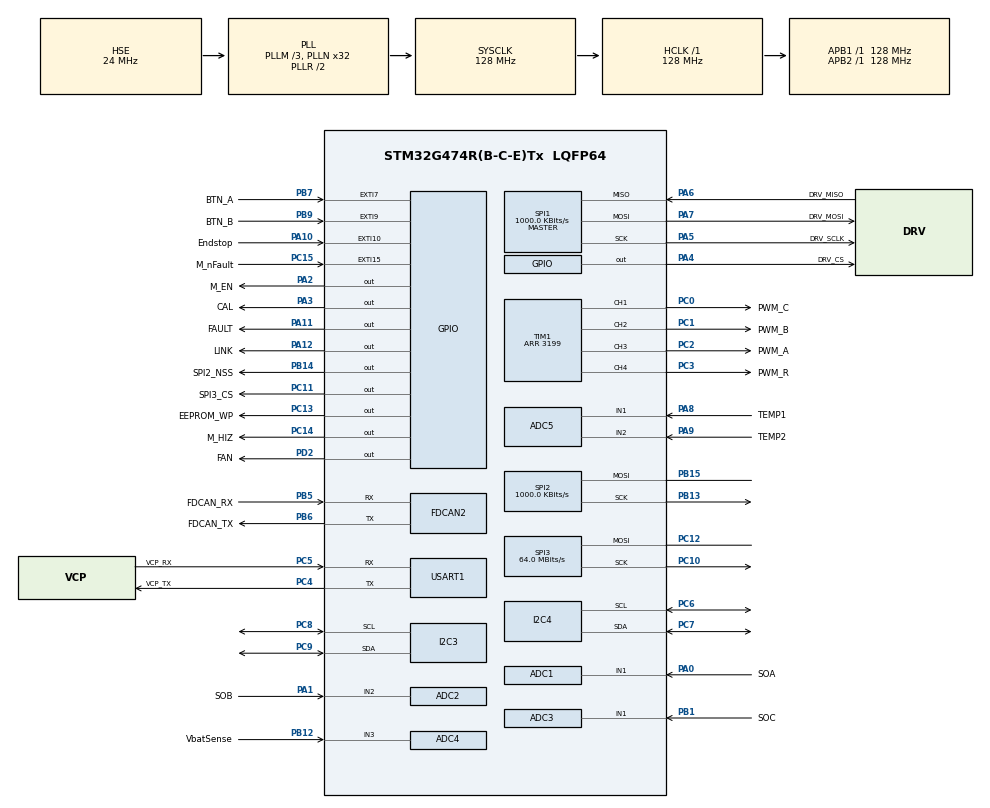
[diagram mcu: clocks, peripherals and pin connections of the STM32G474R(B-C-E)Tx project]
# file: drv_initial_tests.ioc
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ADC1.Channel-0\#ChannelRegularConversion=ADC_CHANNEL_1
ADC1.ClockPrescaler=ADC_CLOCK_ASYNC_DIV10
ADC1.ContinuousConvMode=DISABLE
ADC1.DMAContinuousRequests=ENABLE
ADC1.EnableInjectedConversion=DISABLE
ADC1.ExternalTrigConv=ADC_EXTERNALTRIG_T1_TRGO2
ADC1.NbrOfConversionFlag=1
ADC1.OffsetNumber-0\#ChannelRegularConversion=ADC_OFFSET_NONE
ADC1.Rank-0\#ChannelRegularConversion=1
ADC1.SamplingTime-0\#ChannelRegularConversion=ADC_SAMPLETIME_6CYCLES_5
ADC1.master=1
ADC2.Channel-0\#ChannelRegularConversion=ADC_CHANNEL_2
ADC2.ClockPrescaler=ADC_CLOCK_ASYNC_DIV10
ADC2.ContinuousConvMode=DISABLE
ADC2.DMAContinuousRequests=ENABLE
ADC2.ExternalTrigConv=ADC_EXTERNALTRIG_T1_TRGO2
ADC2.NbrOfConversionFlag=1
ADC2.OffsetNumber-0\#ChannelRegularConversion=ADC_OFFSET_NONE
ADC2.Rank-0\#ChannelRegularConversion=1
ADC2.SamplingTime-0\#ChannelRegularConversion=ADC_SAMPLETIME_6CYCLES_5
ADC3.Channel-5\#ChannelRegularConversion=ADC_CHANNEL_1
ADC3.ClockPrescaler=ADC_CLOCK_ASYNC_DIV10
ADC3.ContinuousConvMode=DISABLE
ADC3.DMAContinuousRequests=ENABLE
ADC3.ExternalTrigConv=ADC_EXTERNALTRIG_T1_TRGO2
ADC3.NbrOfConversionFlag=1
ADC3.OffsetNumber-5\#ChannelRegularConversion=ADC_OFFSET_NONE
ADC3.Rank-5\#ChannelRegularConversion=1
ADC3.SamplingTime-5\#ChannelRegularConversion=ADC_SAMPLETIME_6CYCLES_5
ADC3.master=1
ADC4.Channel-8\#ChannelRegularConversion=ADC_CHANNEL_3
ADC4.ClockPrescaler=ADC_CLOCK_ASYNC_DIV10
ADC4.NbrOfConversionFlag=1
ADC4.OffsetNumber-8\#ChannelRegularConversion=ADC_OFFSET_NONE
ADC4.Rank-8\#ChannelRegularConversion=1
ADC4.SamplingTime-8\#ChannelRegularConversion=ADC_SAMPLETIME_2CYCLES_5
ADC5.Channel-0\#ChannelRegularConversion=ADC_CHANNEL_1
ADC5.ClockPrescaler=ADC_CLOCK_ASYNC_DIV10
ADC5.ContinuousConvMode=ENABLE
ADC5.NbrOfConversionFlag=1
ADC5.OffsetNumber-0\#ChannelRegularConversion=ADC_OFFSET_NONE
ADC5.Rank-0\#ChannelRegularConversion=1
ADC5.SamplingTime-0\#ChannelRegularConversion=ADC_SAMPLETIME_2CYCLES_5
Dma.ADC1.0.Direction=DMA_PERIPH_TO_MEMORY
Dma.ADC1.0.EventEnable=DISABLE
Dma.ADC1.0.Instance=DMA1_Channel1
Dma.ADC1.0.MemDataAlignment=DMA_MDATAALIGN_HALFWORD
Dma.ADC1.0.MemInc=DMA_MINC_DISABLE
Dma.ADC1.0.Mode=DMA_CIRCULAR
Dma.ADC1.0.PeriphDataAlignment=DMA_PDATAALIGN_HALFWORD
Dma.ADC1.0.PeriphInc=DMA_PINC_DISABLE
Dma.ADC1.0.Polarity=HAL_DMAMUX_REQ_GEN_RISING
Dma.ADC1.0.Priority=DMA_PRIORITY_LOW
Dma.ADC1.0.RequestNumber=1
Dma.ADC1.0.SignalID=NONE
Dma.ADC1.0.SyncEnable=DISABLE
Dma.ADC1.0.SyncPolarity=HAL_DMAMUX_SYNC_NO_EVENT
Dma.ADC1.0.SyncRequestNumber=1
Dma.ADC1.0.SyncSignalID=NONE
Dma.ADC2.1.Direction=DMA_PERIPH_TO_MEMORY
Dma.ADC2.1.EventEnable=DISABLE
Dma.ADC2.1.Instance=DMA1_Channel2
Dma.ADC2.1.MemDataAlignment=DMA_MDATAALIGN_HALFWORD
Dma.ADC2.1.MemInc=DMA_MINC_DISABLE
Dma.ADC2.1.Mode=DMA_CIRCULAR
Dma.ADC2.1.PeriphDataAlignment=DMA_PDATAALIGN_HALFWORD
Dma.ADC2.1.PeriphInc=DMA_PINC_DISABLE
Dma.ADC2.1.Polarity=HAL_DMAMUX_REQ_GEN_RISING
Dma.ADC2.1.Priority=DMA_PRIORITY_LOW
Dma.ADC2.1.RequestNumber=1
Dma.ADC2.1.SignalID=NONE
Dma.ADC2.1.SyncEnable=DISABLE
Dma.ADC2.1.SyncPolarity=HAL_DMAMUX_SYNC_NO_EVENT
Dma.ADC2.1.SyncRequestNumber=1
Dma.ADC2.1.SyncSignalID=NONE
Dma.ADC3.2.Direction=DMA_PERIPH_TO_MEMORY
Dma.ADC3.2.EventEnable=DISABLE
Dma.ADC3.2.Instance=DMA1_Channel3
Dma.ADC3.2.MemDataAlignment=DMA_MDATAALIGN_HALFWORD
Dma.ADC3.2.MemInc=DMA_MINC_DISABLE
Dma.ADC3.2.Mode=DMA_CIRCULAR
Dma.ADC3.2.PeriphDataAlignment=DMA_PDATAALIGN_HALFWORD
Dma.ADC3.2.PeriphInc=DMA_PINC_DISABLE
Dma.ADC3.2.Polarity=HAL_DMAMUX_REQ_GEN_RISING
Dma.ADC3.2.Priority=DMA_PRIORITY_LOW
Dma.ADC3.2.RequestNumber=1
Dma.ADC3.2.SignalID=NONE
Dma.ADC3.2.SyncEnable=DISABLE
Dma.ADC3.2.SyncPolarity=HAL_DMAMUX_SYNC_NO_EVENT
Dma.ADC3.2.SyncRequestNumber=1
Dma.ADC3.2.SyncSignalID=NONE
Dma.Request0=ADC1
Dma.Request1=ADC2
Dma.Request2=ADC3
FDCAN2.AutoRetransmission=ENABLE
FDCAN2.CalculateBaudRateNominal=2666666
FDCAN2.CalculateTimeBitNominal=375
FDCAN2.CalculateTimeQuantumNominal=125.0
I2C3.Timing=0x20E2A7F4
I2C4.Timing=0x20E2A7F4
IWDG.Prescaler=IWDG_PRESCALER_32
Mcu.Family=STM32G4
Mcu.Name=STM32G474R(B-C-E)Tx
Mcu.Package=LQFP64
NVIC.DMA1_Channel1_IRQn=true\:0\:0\:false\:false\:true\:false\:true\:true
NVIC.DMA1_Channel2_IRQn=true\:0\:0\:false\:false\:true\:false\:true\:true
NVIC.DMA1_Channel3_IRQn=true\:0\:0\:false\:false\:true\:false\:true\:true
NVIC.EXTI15_10_IRQn=true\:3\:0\:true\:false\:true\:true\:true\:true
NVIC.EXTI9_5_IRQn=true\:2\:0\:true\:false\:true\:true\:true\:true
NVIC.PriorityGroup=NVIC_PRIORITYGROUP_4
NVIC.TIM1_UP_TIM16_IRQn=true\:0\:0\:false\:false\:true\:true\:true\:true
NVIC.TIM6_DAC_IRQn=true\:1\:0\:true\:false\:true\:true\:true\:true
NVIC.TIM7_DAC_IRQn=true\:2\:0\:true\:false\:true\:true\:true\:true
PA0.GPIO_Label=SOA
PA0.Mode=IN1-Single-Ended
PA0.Signal=ADC1_IN1
PA1.GPIO_Label=SOB
PA1.Mode=IN2-Single-Ended
PA1.Signal=ADC2_IN2
PA10.GPIO_Label=Endstop
PA10.Signal=GPXTI10
PA11.GPIO_Label=FAULT
PA11.PinState=GPIO_PIN_SET
PA11.Signal=GPIO_Output
PA12.GPIO_Label=LINK
PA12.PinState=GPIO_PIN_SET
PA12.Signal=GPIO_Output
PA13.Mode=JTAG_5_pins
PA13.Signal=SYS_JTMS-SWDIO
PA14.Mode=JTAG_5_pins
PA14.Signal=SYS_JTCK-SWCLK
PA15.Mode=JTAG_5_pins
PA15.Signal=SYS_JTDI
PA2.GPIO_Label=M_EN
PA2.Signal=GPIO_Output
PA3.GPIO_Label=CAL
PA3.Signal=GPIO_Output
PA4.GPIO_Label=DRV_CS
PA4.PinState=GPIO_PIN_SET
PA4.Signal=GPIO_Output
PA5.GPIO_Label=DRV_SCLK
PA5.Mode=Full_Duplex_Master
PA5.Signal=SPI1_SCK
PA6.GPIO_Label=DRV_MISO
PA6.Mode=Full_Duplex_Master
PA6.Signal=SPI1_MISO
PA7.GPIO_Label=DRV_MOSI
PA7.Mode=Full_Duplex_Master
PA7.Signal=SPI1_MOSI
PA8.GPIO_Label=TEMP1
PA8.Mode=IN1-Single-Ended
PA8.Signal=ADC5_IN1
PA9.GPIO_Label=TEMP2
PA9.Mode=IN2-Single-Ended
PA9.Signal=ADC5_IN2
PB1.GPIO_Label=SOC
PB1.Mode=IN1-Single-Ended
PB1.Signal=ADC3_IN1
PB12.GPIO_Label=VbatSense
PB12.Mode=IN3-Single-Ended
PB12.Signal=ADC4_IN3
PB13.Mode=Simplex_Bidirectional_Master
PB13.Signal=SPI2_SCK
PB14.GPIO_Label=SPI2_NSS
PB14.PinState=GPIO_PIN_SET
PB14.Signal=GPIO_Output
PB15.Mode=Simplex_Bidirectional_Master
PB15.Signal=SPI2_MOSI
PB3.Mode=JTAG_5_pins
PB3.Signal=SYS_JTDO-SWO
PB4.Mode=JTAG_5_pins
PB4.Signal=SYS_JTRST
PB5.GPIO_Label=FDCAN_RX
PB5.Mode=FDCAN_Activate
PB5.Signal=FDCAN2_RX
PB6.GPIO_Label=FDCAN_TX
PB6.Mode=FDCAN_Activate
PB6.Signal=FDCAN2_TX
PB7.GPIO_Label=BTN_A
PB7.GPIO_ModeDefaultEXTI=GPIO_MODE_IT_FALLING
PB7.GPIO_PuPd=GPIO_PULLUP
PB7.Signal=GPXTI7
PB9.GPIO_Label=BTN_B
PB9.GPIO_ModeDefaultEXTI=GPIO_MODE_IT_FALLING
PB9.GPIO_PuPd=GPIO_PULLUP
PB9.Signal=GPXTI9
PC0.GPIO_Label=PWM_C
PC0.Signal=S_TIM1_CH1
PC1.GPIO_Label=PWM_B
PC1.Signal=S_TIM1_CH2
PC10.Mode=Simplex_Bidirectional_Master
PC10.Signal=SPI3_SCK
PC11.GPIO_Label=SPI3_CS
PC11.PinState=GPIO_PIN_SET
PC11.Signal=GPIO_Output
PC12.Mode=Simplex_Bidirectional_Master
PC12.Signal=SPI3_MOSI
PC13.GPIO_Label=EEPROM_WP
PC13.Signal=GPIO_Output
PC14-OSC32_IN.GPIO_Label=M_HIZ
PC14-OSC32_IN.Signal=GPIO_Output
PC15-OSC32_OUT.GPIO_Label=M_nFault
PC15-OSC32_OUT.GPIO_ModeDefaultEXTI=GPIO_MODE_IT_FALLING
PC15-OSC32_OUT.Signal=GPXTI15
PC2.GPIO_Label=PWM_A
PC2.Signal=S_TIM1_CH3
PC3.GPIO_Label=PWM_R
PC3.Signal=S_TIM1_CH4
PC4.GPIO_Label=VCP_TX
PC4.Mode=Asynchronous
PC4.Signal=USART1_TX
PC5.GPIO_Label=VCP_RX
PC5.Mode=Asynchronous
PC5.Signal=USART1_RX
PC6.Mode=I2C
PC6.Signal=I2C4_SCL
PC7.Mode=I2C
PC7.Signal=I2C4_SDA
PC8.Mode=I2C
PC8.Signal=I2C3_SCL
PC9.Mode=I2C
PC9.Signal=I2C3_SDA
PD2.GPIO_Label=FAN
PD2.Signal=GPIO_Output
PF0-OSC_IN.Mode=HSE-External-Oscillator
PF0-OSC_IN.Signal=RCC_OSC_IN
PF1-OSC_OUT.Mode=HSE-External-Oscillator
PF1-OSC_OUT.Signal=RCC_OSC_OUT
ProjectManager.HeapSize=0x200
ProjectManager.StackSize=0x400
ProjectManager.TargetToolchain=STM32CubeIDE
RCC.ADC12Freq_Value=128000000
RCC.ADC345Freq_Value=128000000
RCC.AHBFreq_Value=128000000
RCC.APB1Freq_Value=128000000
RCC.APB1TimFreq_Value=128000000
RCC.APB2Freq_Value=128000000
RCC.APB2TimFreq_Value=128000000
RCC.CortexFreq_Value=128000000
RCC.EXTERNAL_CLOCK_VALUE=12288000
RCC.HCLKFreq_Value=128000000
RCC.HSE_VALUE=24000000
RCC.HSI48_VALUE=48000000
RCC.HSI_VALUE=16000000
RCC.LSE_VALUE=32768
RCC.PLLM=RCC_PLLM_DIV3
RCC.PLLN=32
RCC.PLLSourceVirtual=RCC_PLLSOURCE_HSE
RCC.SYSCLKFreq_VALUE=128000000
RCC.SYSCLKSource=RCC_SYSCLKSOURCE_PLLCLK
RCC.USBFreq_Value=128000000
RCC.VCOOutputFreq_Value=256000000
SH.S_TIM1_CH1.0=TIM1_CH1,PWM Generation1 CH1
SH.S_TIM1_CH2.0=TIM1_CH2,PWM Generation2 CH2
SH.S_TIM1_CH3.0=TIM1_CH3,PWM Generation3 CH3
SH.S_TIM1_CH4.0=TIM1_CH4,PWM Generation4 CH4
SPI1.BaudRatePrescaler=SPI_BAUDRATEPRESCALER_128
SPI1.CLKPhase=SPI_PHASE_2EDGE
SPI1.CalculateBaudRate=1000.0 KBits/s
SPI1.DataSize=SPI_DATASIZE_16BIT
SPI1.Direction=SPI_DIRECTION_2LINES
SPI1.Mode=SPI_MODE_MASTER
SPI1.VirtualType=VM_MASTER
SPI2.BaudRatePrescaler=SPI_BAUDRATEPRESCALER_128
SPI2.CLKPhase=SPI_PHASE_2EDGE
SPI2.CalculateBaudRate=1000.0 KBits/s
SPI2.DataSize=SPI_DATASIZE_8BIT
SPI2.Direction=SPI_DIRECTION_1LINE
SPI2.Mode=SPI_MODE_MASTER
SPI2.VirtualType=VM_MASTER
SPI3.CalculateBaudRate=64.0 MBits/s
SPI3.Direction=SPI_DIRECTION_1LINE
SPI3.Mode=SPI_MODE_MASTER
SPI3.VirtualType=VM_MASTER
TIM1.Channel-Output\ Compare5\ No\ Output=TIM_CHANNEL_5
TIM1.Channel-PWM\ Generation1\ CH1=TIM_CHANNEL_1
TIM1.Channel-PWM\ Generation2\ CH2=TIM_CHANNEL_2
TIM1.Channel-PWM\ Generation3\ CH3=TIM_CHANNEL_3
TIM1.Channel-PWM\ Generation4\ CH4=TIM_CHANNEL_4
TIM1.CounterMode=TIM_COUNTERMODE_CENTERALIGNED1
TIM1.OC5Preload=DISABLE
TIM1.OCMode_5=TIM_OCMODE_TOGGLE
TIM1.PeriodNoDither=3199
TIM1.PulseNoDither_5=1599
TIM1.TIM_MasterOutputTrigger2=TIM_TRGO2_OC5REF
TIM6.PeriodNoDither=25599
TIM7.PeriodNoDither=39999
TIM7.Prescaler=15
USART1.VirtualMode-Asynchronous=VM_ASYNC
VP_IWDG_VS_IWDG.Mode=IWDG_Activate
VP_SYS_VS_DBSignals.Mode=DisableDeadBatterySignals
VP_TIM1_VS_ClockSourceINT.Mode=Internal
VP_TIM1_VS_no_output5.Mode=Output Compare5 No Output
VP_TIM6_VS_ClockSourceINT.Mode=Enable_Timer
VP_TIM7_VS_ClockSourceINT.Mode=Enable_Timer
board=custom

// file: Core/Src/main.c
/* USER CODE BEGIN Header */
/**
  ******************************************************************************
  * @file           : main.c
  * @brief          : Main program body
  ******************************************************************************
  * @attention
  *
  * Copyright (c) 2025 STMicroelectronics.
  * All rights reserved.
  *
  * This software is licensed under terms that can be found in the LICENSE file
  * in the root directory of this software component.
  * If no LICENSE file comes with this software, it is provided AS-IS.
  *
  ******************************************************************************
  */
/* USER CODE END Header */
#include "main.h"

/* USER CODE BEGIN Includes */
#include <stdbool.h>
#include <string.h>
#include <stdio.h>
#include <math.h>
#include "TLE_encoder.h"
#include <stdlib.h>
/* USER CODE END Includes */

ADC_HandleTypeDef hadc1;
ADC_HandleTypeDef hadc2;
ADC_HandleTypeDef hadc3;
ADC_HandleTypeDef hadc4;
ADC_HandleTypeDef hadc5;
DMA_HandleTypeDef hdma_adc1;
DMA_HandleTypeDef hdma_adc2;
DMA_HandleTypeDef hdma_adc3;

FDCAN_HandleTypeDef hfdcan2;

I2C_HandleTypeDef hi2c3;
I2C_HandleTypeDef hi2c4;

IWDG_HandleTypeDef hiwdg;

SPI_HandleTypeDef hspi1;
SPI_HandleTypeDef hspi2;
SPI_HandleTypeDef hspi3;

TIM_HandleTypeDef htim1;
TIM_HandleTypeDef htim6;
TIM_HandleTypeDef htim7;

UART_HandleTypeDef huart1;

/* USER CODE BEGIN PV */
//--DRV8323 register definitions------------------------------------------------
// Read-only status registers
#define DRV8323_REG_FAULT_STATUS_1    0x00  // Fault Status Register 1
#define DRV8323_REG_VGS_STATUS_2      0x01  // VGS Fault Status Register 2
// Control and configuration registers
#define DRV8323_REG_DRIVER_CONTROL    0x02  // Driver Control Register
#define DRV8323_REG_GATE_DRIVE_HS     0x03  // High Side Gate Drive Control
#define DRV8323_REG_GATE_DRIVE_LS     0x04  // Low Side Gate Drive Control
#define DRV8323_REG_OCP_CONTROL       0x05  // Over Current Protection Control
#define DRV8323_REG_CSA_CONTROL       0x06  // Current Sense Amplifier Control

#define DRV8323_RW_WRITE  0x0000       // bit15 = 0 → write
#define DRV8323_RW_READ   0x8000       // bit15 = 1 → read
//------------------------------------------------------------------------------
// Motor control definitions
#define SINE_TABLE_SIZE     256
uint16_t sine_table[SINE_TABLE_SIZE];
#define TIM1_FULL_DUTY      3199//1599  //2*1600-1 for 128Mhz timer clock and 40kHz PWM - 1600 because 0 - 1599 Counter period
#define TIM6_UPDATE_FREQ    5000
#define MOTOR_POLE_PAIRS    20
#define MOTOR_RATED_RPM     2000.0f
#define MAX_RPM             2000.0f
#define MIN_RPM             -(MAX_RPM)
#define RPM_STEP            500.0f
// Filtered speed for control
static float rpm_filtered = 0.0f;
#define SPEED_FILTER_ALPHA  0.2f   // between 0 and 1
#define SPEED_I_BAND_RPM  100.0f   // integrate only when |err| < 100 rpm

/* Motion variables */
float encoder_electrical_offset = 0.0f;  // add 180 deg when field direction is reversed
volatile float intermediate_rpm = 0.0f;
volatile float target_rpm  = 0.0f;
volatile bool  motor_running = false;
float speed_increment = 0.0f;
uint16_t voltage_amplitude = 0;
/* Phase accumulators */
volatile float phaseA=0.f, phaseB=SINE_TABLE_SIZE/3.f, phaseC=SINE_TABLE_SIZE/3.f*2.f;
/* DRV fault flag */
volatile bool drv_fault_active = false;   // Interrupt flag: nFAULT went low
volatile uint16_t drv_fault_reg1 = 0;
volatile uint16_t drv_fault_reg2 = 0;

//Pi speed controller variable
static float speed_err_int = 0.0f;
// Tune these experimentally (start small)
#define SPEED_KP  0.2f   // proportional gain
#define SPEED_KI  0.3f   // integral gain

// Command limits
#define RPM_CMD_MAX  MAX_RPM   // upper limit of commanded RPM
#define RPM_CMD_MIN  MIN_RPM      // lower limit

// V/f amplitude settings
#define VF_MAX_AMPLITUDE  0.95f   // 50 % of TIM1_FULL_DUTY at MAX_RPM
#define VF_MIN_AMPLITUDE  0.15f  // 15 % minimum when running
#define SPEED_INCREMENT_MAX   (SINE_TABLE_SIZE / 5.0f)  // ≈ 51.2 for 512/10
// Max acceleration of commanded mechanical speed (rpm per second)
#define ACCEL_LIMIT_RPM_PER_SEC  300.0f
#define DECCEL_LIMIT_RPM_PER_SEC 300.0f
#define SUPPLY_VOLTAGE      24.0f
#define MOTOR_KV_RPM_PER_V  90.0f
// Position control variables
#define GEAR_RATIO  25.0f
#define POS_LOOP_DT             0.01f    // 10 ms 100Hz (not too slow?)
#define POS_KP                  1.9f     // rpm per degree of output error
#define POS_KI                 0.2f     // rpm per (rpm of motor), damping
#define POS_DEADBAND_DEG        0.1f     // don't chase very small errors

volatile float target_pos_out_deg = 0.0f;  // desired output angle
static   float pos_err_int        = 0.0f;  // integrator for position PI
static uint8_t pos_loop_divider = 0;
#define ANGLE_DISPLAY_OFFSET_DEG  -5.0f+13.0f-14.0f

volatile uint16_t adc_phase_raw[3];
// Midpoint (zero-current) ADC codes, measured during calibration
float adc_mid_A = 0.0f;
float adc_mid_B = 0.0f;
float adc_mid_C = 0.0f;
#define ADC_FULL_SCALE_COUNTS 4096.0f
#define CURR_RSENSE_OHM       0.001f
#define CURR_CSA_GAIN         40.0f
#define CURR_VREF             3.287f
const float CURR_A_PER_COUNT = (CURR_VREF / (ADC_FULL_SCALE_COUNTS * CURR_CSA_GAIN * CURR_RSENSE_OHM)); //20mA

volatile float dbg_ia = 0.0f;
volatile float dbg_ib = 0.0f;
volatile float dbg_ic = 0.0f;
volatile float dbg_angle = 0.0f;
/* USER CODE END PV */

void SystemClock_Config(void);
static void MX_GPIO_Init(void);
static void MX_DMA_Init(void);
static void MX_FDCAN2_Init(void);
static void MX_ADC1_Init(void);
static void MX_ADC2_Init(void);
static void MX_ADC3_Init(void);
static void MX_ADC5_Init(void);
static void MX_SPI1_Init(void);
static void MX_SPI2_Init(void);
static void MX_SPI3_Init(void);
static void MX_TIM1_Init(void);
static void MX_I2C3_Init(void);
static void MX_USART1_UART_Init(void);
static void MX_I2C4_Init(void);
static void MX_ADC4_Init(void);
static void MX_TIM6_Init(void);
static void MX_IWDG_Init(void);
static void MX_TIM7_Init(void);

/* USER CODE BEGIN 0 */
TLE_Encoder_t encoder;
// Write register
// ============================================================================
// Frame format: [15]=RW | [14:11]=Address | [10:0]=Data
// ============================================================================
void drv8323_reg_write(uint8_t reg, uint16_t value) {
    uint16_t frame = DRV8323_RW_WRITE | ((reg & 0x0F) << 11) | (value & 0x07FF);

    HAL_GPIO_WritePin(DRV_CS_GPIO_Port, DRV_CS_Pin, GPIO_PIN_RESET); // CS low
    HAL_SPI_Transmit(&hspi1, (uint8_t *)&frame, 1, HAL_MAX_DELAY);
    HAL_GPIO_WritePin(DRV_CS_GPIO_Port, DRV_CS_Pin, GPIO_PIN_SET);   // CS high
    HAL_Delay(1); // Small delay to ensure proper timing
}

/* prawie działa - do poprawy
uint16_t drv8323_reg_read(uint8_t reg) {
    uint16_t frame = DRV8323_RW_READ | ((reg & 0x0F) << 11);
    uint16_t dummy = 0x0000;
    uint16_t received_frame = 0;

    HAL_Delay(10);

    HAL_GPIO_WritePin(DRV8323_CS_GPIO_Port, DRV8323_CS_Pin, GPIO_PIN_RESET);
    HAL_SPI_Transmit(&hspi3, (uint8_t *)&dummy, 1, HAL_MAX_DELAY);
    HAL_SPI_Receive(&hspi3, (uint8_t *)&received_frame, 1, HAL_MAX_DELAY);
    HAL_GPIO_WritePin(DRV8323_CS_GPIO_Port, DRV8323_CS_Pin, GPIO_PIN_SET);
    HAL_Delay(1);

    return received_frame;
}

*/

/* ====================  SETINGS for DRV8323  ==================== */
void DRV8323_Init(void)
{

    // 0. Disable nFAULT EXTI interrupt during DRV startup
    HAL_NVIC_DisableIRQ(EXTI9_5_IRQn);
    __HAL_GPIO_EXTI_CLEAR_FLAG(M_nFault_Pin); // clear any pending edge
    HAL_GPIO_WritePin(M_HIZ_GPIO_Port, M_HIZ_Pin, GPIO_PIN_RESET);
    HAL_GPIO_WritePin(M_EN_GPIO_Port, M_EN_Pin, GPIO_PIN_SET);
    HAL_Delay(10);
    HAL_GPIO_WritePin(DRV_CS_GPIO_Port, DRV_CS_Pin, GPIO_PIN_SET);

    HAL_Delay(10);

	// 4. Settings
    drv8323_reg_write(DRV8323_REG_GATE_DRIVE_HS, 0x0FC);  // HS IDRIVE 1000/1140 mA
    drv8323_reg_write(DRV8323_REG_GATE_DRIVE_LS, 0x3FC);  // LS IDRIVE 1000/1140 mA, 2 µs tdrive
    drv8323_reg_write(DRV8323_REG_OCP_CONTROL,   0x359);  // Deadtime 400 ns, auto‑retry, 4 µs deglitch
    drv8323_reg_write(DRV8323_REG_CSA_CONTROL,   0x2C3);  // 40 V/V gain, bidirectional
    drv8323_reg_write(DRV8323_REG_DRIVER_CONTROL,0x0A0);  // 3× PWM, protections active

       __HAL_GPIO_EXTI_CLEAR_FLAG(M_nFault_Pin);
       HAL_NVIC_EnableIRQ(EXTI9_5_IRQn);
}

/* ==================== SINE TABLE ==================== */
void Generate_Sine_Table(void)
{
    for (uint16_t i = 0; i < SINE_TABLE_SIZE; i++)
    {
        float angle=(2.0f * M_PI * i) / SINE_TABLE_SIZE;
        float sin_norm=(sinf(angle) + 1.0f) * 0.5f;
        sine_table[i]=(uint16_t)(sin_norm * TIM1_FULL_DUTY);
    }
}

/* ==================== ALIGNMENT ===================== */
void Motor_Align(void)
{

	HAL_TIM_Base_Stop_IT(&htim6); // stop timer interrupt
    voltage_amplitude=TIM1_FULL_DUTY/15;
    //Energise one phase to align rotor
    __HAL_TIM_SET_COMPARE(&htim1,TIM_CHANNEL_1,voltage_amplitude);
    __HAL_TIM_SET_COMPARE(&htim1,TIM_CHANNEL_2,0);
    __HAL_TIM_SET_COMPARE(&htim1,TIM_CHANNEL_3,0);

    HAL_Delay(300); // wait for rotor to align

    __HAL_TIM_SET_COMPARE(&htim1, TIM_CHANNEL_1, 0);

    phaseA = 0.0f;
    phaseB = SINE_TABLE_SIZE / 3.0f;
    phaseC = 2.0f * SINE_TABLE_SIZE / 3.0f;
    // Also safe to reset speed command at start
    intermediate_rpm = 0.0f;
    speed_increment  = 0.0f;

    // Re-enable PWM updates
    HAL_TIM_Base_Start_IT(&htim6);

}
static void ResetControllersForNewMove(void)
{
    // Position PI
    pos_err_int = 0.0f;

    // Speed PI
    speed_err_int = 0.0f;

    // Speed / ramp state
    rpm_filtered     = 0.0f;
    intermediate_rpm = 0.0f;
    speed_increment  = 0.0f;

    // Make sure speed command starts from zero
    target_rpm = 0.0f;
}
// ==================== SPEED CALCULATION =====================
#define NUM_SAMPLES 5
uint8_t divider = 10;
int8_t coefficients[5] = {2, 1, 0, -1, -2};
float y[NUM_SAMPLES] = {0};  // newest → oldest
uint8_t sample_count = 0;
float dt = 0.005f;
float speed = 0.0f;
float last_angle = 0.0f;
float angle_unwrapped = 0.0f;

// Called every 5 ms (200 Hz)
void TLE_Encoder_CalcSpeed(TLE_Encoder_t *enc)
{
    // Read current angle
    float angle = TLE_Encoder_ReadAngle(enc);
    float delta = angle - last_angle;

        if (delta > 180.0f) {
            // wrapped backward (e.g. 359 → 1)
            angle_unwrapped -= (360.0f - delta);
        } else if (delta < -180.0f) {
            // wrapped forward (e.g. 1 → 359)
            angle_unwrapped += (360.0f + delta);
        } else {
            angle_unwrapped += delta;
        }
        // Update last angle
        last_angle = angle;

    // Shift older samples down
    for (int i = NUM_SAMPLES - 1; i > 0; i--) {
        y[i] = y[i - 1];
    }

    // Store newest sample at index 0
    y[0] = angle_unwrapped;
    if (sample_count < NUM_SAMPLES)
    {
        sample_count++;
    }
    if (sample_count >= NUM_SAMPLES)
        {
    	float result = 0.0f;
        for (int i = 0; i < NUM_SAMPLES; i++)
        {
            result += coefficients[i] * y[i];
        }
        speed = result / (dt * divider);
    		enc->data.rpm = speed/6.0f; // convert deg/s to RPM
    		enc->data.angle_multi_deg = angle_unwrapped; //probably no need for so many decimal places it makes computation slower
        }
}

void SpeedLoop_Update(void)
{
    if (!motor_running || drv_fault_active) {
        intermediate_rpm = 0.0f;
        speed_increment  = 0.0f;
        speed_err_int    = 0.0f;
        return;
    }

    float rpm_meas_raw = TLE_Encoder_GetSpeed(&encoder);
    // Low-pass filter
    rpm_filtered += SPEED_FILTER_ALPHA * (rpm_meas_raw - rpm_filtered);
    // Use rpm_filtered for the controller
    float rpm_meas = rpm_filtered;
    float err      = target_rpm - rpm_meas;

    // Proportional term only (no I yet)
    float p_term = SPEED_KP * err;

    // First build unsaturated command using current integrator
    float rpm_cmd_unsat = target_rpm + p_term + SPEED_KI * speed_err_int;

    // Compute the effective upper limit (speed limit AND increment limit)
    float rpm_limit_by_inc =
        (SPEED_INCREMENT_MAX * 60.0f * TIM6_UPDATE_FREQ) /
        (MOTOR_POLE_PAIRS * SINE_TABLE_SIZE);

    float upper_limit = RPM_CMD_MAX;
    if (rpm_limit_by_inc < upper_limit) {
        upper_limit = rpm_limit_by_inc;
    }

    // Apply saturation
    float rpm_cmd = rpm_cmd_unsat;
    if (rpm_cmd > upper_limit) rpm_cmd = upper_limit;
    if (rpm_cmd < RPM_CMD_MIN) rpm_cmd = RPM_CMD_MIN;

    // Anti-windup: only integrate if we are NOT saturating in the same
    // direction as the error
    bool sat_high = (rpm_cmd >= upper_limit - 1e-3f);
    bool sat_low  = (rpm_cmd <= RPM_CMD_MIN + 1e-3f);

    // Integrate only when close to target and not pushing into a limit
    if (fabsf(err) < SPEED_I_BAND_RPM &&
        !((sat_high && err > 0.0f) || (sat_low && err < 0.0f)))
    {
        speed_err_int += err * dt;
    }
    else if (fabsf(err) > 2.0f * SPEED_I_BAND_RPM)
    {
        // Optional: reset integrator when far away to avoid old windup
        speed_err_int = 0.0f;
    }
/*
    intermediate_rpm = rpm_cmd;

    // Convert commanded mechanical RPM to electrical phase increment
    speed_increment =
        (intermediate_rpm * MOTOR_POLE_PAIRS * SINE_TABLE_SIZE) /
        (60.0f * TIM6_UPDATE_FREQ);
        */
    // Rate limiting: limit how fast intermediate_rpm can change
    float max_step_up   = ACCEL_LIMIT_RPM_PER_SEC * dt;       // speed up
       float max_step_down = DECCEL_LIMIT_RPM_PER_SEC * dt; // 4x faster slow down

       float drpm = rpm_cmd - intermediate_rpm;

       if (drpm > 0.0f) {
           // accelerating
           if (drpm > max_step_up) {
               drpm = max_step_up;
           }
       } else {
           // decelerating (drpm <= 0)
           if (drpm < -max_step_down) {
               drpm = -max_step_down;
           }
       }

       intermediate_rpm += drpm;

       // Convert commanded mechanical RPM to electrical phase increment
       speed_increment =
           (intermediate_rpm * MOTOR_POLE_PAIRS * SINE_TABLE_SIZE) /
           (60.0f * TIM6_UPDATE_FREQ);
}
void PositionLoop_Update(float dt_loop)
{
    if (!motor_running || drv_fault_active) {
        pos_err_int = 0.0f;
        return;
    }

    // Motor angle (multi-turn) in degrees
    float motor_angle_deg = TLE_Encoder_GetAngleMultiDeg(&encoder);

    // Output shaft angle
    float pos_out_deg = motor_angle_deg / GEAR_RATIO;

    float pos_err_deg = target_pos_out_deg - pos_out_deg;

    // Deadband
    if (fabsf(pos_err_deg) < POS_DEADBAND_DEG) {
        // If we're very close AND already almost stopped, then treat as "at rest"
        if (fabsf(rpm_filtered) < 1.0f) {  // tune this threshold
            pos_err_int   = 0.0f;
            target_rpm    = 0.0f;

            speed_err_int    = 0.0f;
            intermediate_rpm = 0.0f;
            speed_increment  = 0.0f;
            rpm_filtered     = 0.0f;
        } else {
            // Close to target but still moving: don't drive I, but let speed loop brake
            pos_err_int = 0.0f;
            target_rpm  = 0.0f;
        }
        return;
    }
    // Compute proportional term
    float p_term = POS_KP * pos_err_deg;

    // Compute tentative integrator update
    float pos_err_int_new = pos_err_int + pos_err_deg * dt_loop;

    // Optional: limit integrator magnitude (prevents huge values)
    const float POS_I_MAX = 200.0f;  // tune as needed (rpm/ Ki)
    if (pos_err_int_new > POS_I_MAX)  pos_err_int_new = POS_I_MAX;
    if (pos_err_int_new < -POS_I_MAX) pos_err_int_new = -POS_I_MAX;

    // Unsaturated PI output
    float cmd_rpm_unsat = p_term + POS_KI * pos_err_int_new;

    // Saturate
    float cmd_rpm = cmd_rpm_unsat;
    if (cmd_rpm > MAX_RPM)  cmd_rpm = MAX_RPM;
    if (cmd_rpm < MIN_RPM)  cmd_rpm = MIN_RPM;

    // Anti-windup:
    // Only accept the new integrator if we are NOT saturating "into" the limit
    bool sat_high = (cmd_rpm >= MAX_RPM - 1e-3f);
    bool sat_low  = (cmd_rpm <= MIN_RPM + 1e-3f);

    if (!((sat_high && pos_err_deg > 0.0f) || (sat_low && pos_err_deg < 0.0f)))
    {
        // Safe to apply new integrator value
        pos_err_int = pos_err_int_new;
    }
    // else: discard this step's integrator update → no further windup

    target_rpm = cmd_rpm;
}

void Update_VoltageAmplitude(void)
{
    if (!motor_running || drv_fault_active) {
        voltage_amplitude = 0;
        return;
    }

    // Use the commanded (ramped) speed for V/f
    float rpm_for_vf = fabsf(intermediate_rpm);

    if (rpm_for_vf <= 0.5f) {
        // Near zero: no voltage
        voltage_amplitude = 0;
        return;
    }

    // Ideal duty from Kv and bus voltage: rpm / (Kv * Vdc)
    float duty = rpm_for_vf / (MOTOR_KV_RPM_PER_V * SUPPLY_VOLTAGE);

    // Small gain to compensate losses
    duty *= 1.3f;

    // Clamp to safe range when running
    if (duty < VF_MIN_AMPLITUDE)
        duty = VF_MIN_AMPLITUDE;
    if (duty > VF_MAX_AMPLITUDE)
        duty = VF_MAX_AMPLITUDE;

    voltage_amplitude = (uint16_t)(duty * TIM1_FULL_DUTY);
}
#define LINE_MAX_LENGTH 4
static char line_buffer[LINE_MAX_LENGTH + 1];
static uint32_t line_length;
static bool display_active = false;

void line_append(uint8_t value)
{
    if (value == '\r' || value == '\n') {
        if (line_length > 0) {
            line_buffer[line_length] = '\0';

            float val = atof(line_buffer);
            target_pos_out_deg += val;

            // fresh start for this move
            ResetControllersForNewMove();

            if (!motor_running && !drv_fault_active) {
                HAL_GPIO_WritePin(
                    M_HIZ_GPIO_Port,
                    M_HIZ_Pin,
                    GPIO_PIN_SET
                );
                Motor_Align();
                motor_running = true;
                ResetControllersForNewMove();
            }

            display_active = true;

            printf("New target (wrapped): %.2f deg\r\n",
                   fmodf(target_pos_out_deg + 360.0f, 360.0f));

            line_length = 0;
        }
    } else {
        if (line_length >= LINE_MAX_LENGTH) {
            line_length = 0;
        }
        line_buffer[line_length++] = (char)value;
    }
}
/* ==================== FAULT SERVICE ===================== */
void DRV8323_ServiceFault(void)
{
    if (drv_fault_active == false) return;       // nothing to do

    //zeroing variables
    motor_running = false;
    intermediate_rpm = 0;
    target_rpm = 0;
    voltage_amplitude = 0;
    __HAL_TIM_SET_COMPARE(&htim1, TIM_CHANNEL_1, 0);
    __HAL_TIM_SET_COMPARE(&htim1, TIM_CHANNEL_2, 0);
    __HAL_TIM_SET_COMPARE(&htim1, TIM_CHANNEL_3, 0);

    //Read fault registers for debugging/log
    //drv_fault_reg1 = drv8323_reg_read(DRV8323_REG_FAULT_STATUS_1);
    //drv_fault_reg2 = drv8323_reg_read(DRV8323_REG_VGS_STATUS_2);

    // Blink quick feedback
    for(int i = 0; i < 10; i++) {
        HAL_GPIO_TogglePin(LINK_GPIO_Port, LINK_Pin);
        HAL_Delay(50);
    }
    static uint8_t clear_counter = 0;
    if (HAL_GPIO_ReadPin(M_nFault_GPIO_Port, M_nFault_Pin) == GPIO_PIN_SET)
    {
    	if (++clear_counter > 3)
        { // Confirm fault line stable for a few cycles
            drv_fault_active = false;
            drv8323_reg_write(DRV8323_REG_DRIVER_CONTROL, 0x0A1);
            clear_counter = 0;
        }
    }
    else
    {
        clear_counter = 0;
    }

}

void CurrentSense_CalibrateMidpoints(void)
{
    const int N = 1024;
    uint32_t sumA = 0, sumB = 0, sumC = 0;

    for (int i = 0; i < N; i++) {
        // Read current DMA values
        uint16_t a = adc_phase_raw[0];
        uint16_t b = adc_phase_raw[1];
        uint16_t c = adc_phase_raw[2];

        sumA += a;
        sumB += b;
        sumC += c;

        // Wait one or a few PWM periods; 1 ms is simple and safe
        HAL_Delay(1);
    }

    adc_mid_A = (float)sumA / (float)N;
    adc_mid_B = (float)sumB / (float)N;
    adc_mid_C = (float)sumC / (float)N;

    printf("Current midpoints: A=%.1f B=%.1f C=%.1f\r\n",
           adc_mid_A, adc_mid_B, adc_mid_C);
}

void CurrentSense_GetPhaseCurrents(float *ia, float *ib, float *ic)
{
    // Snapshot raw ADC codes (to avoid inconsistency if DMA updates mid‑use)
    uint16_t a_code = adc_phase_raw[0];
    uint16_t b_code = adc_phase_raw[1];
    uint16_t c_code = adc_phase_raw[2];

    // Convert to signed delta around calibrated midpoint
    float da = adc_mid_A - (float)a_code;  // note sign: positive = one direction
    float db = adc_mid_B - (float)b_code;
    float dc = adc_mid_C - (float)c_code;

    // Convert ADC-count delta -> current in A
    *ia = da * CURR_A_PER_COUNT;
    *ib = db * CURR_A_PER_COUNT;
    *ic = dc * CURR_A_PER_COUNT;
}

uint32_t last_press_tick = 0;

void HAL_GPIO_EXTI_Callback(uint16_t GPIO_Pin)
{
	if(GPIO_Pin == M_nFault_Pin)
	{
        // Fast reaction to fault: disable MOSFETs instantly
        HAL_GPIO_WritePin(M_HIZ_GPIO_Port, M_HIZ_Pin, GPIO_PIN_RESET);
        drv_fault_active = true;
        return;
	}
	/* ==================== BUTTON ======================= */
    if (GPIO_Pin == BTN_A_Pin)
    {

        uint32_t now = HAL_GetTick();
        if (now - last_press_tick < 200) return; // ignore if within 200ms of last press
        last_press_tick = now;

        HAL_GPIO_TogglePin(FAULT_GPIO_Port, FAULT_Pin);

        if (!motor_running && !drv_fault_active)
        {
        	HAL_GPIO_WritePin(M_HIZ_GPIO_Port, M_HIZ_Pin, GPIO_PIN_SET); // Enable mosfets
            Motor_Align();
            motor_running = true;
            //float motor_angle = TLE_Encoder_GetAngleMultiDeg(&encoder);
            target_pos_out_deg = 0.0f;                        // define current as 0°
            target_rpm         = 0.0f;
            speed_err_int      = 0.0f;
            pos_err_int        = 0.0f;
        }
        else
        {
        	target_pos_out_deg += 360.0f;
        	ResetControllersForNewMove();

        }
    }
}
void HAL_TIM_PeriodElapsedCallback(TIM_HandleTypeDef *htim)
{
    if (htim == &htim6) {
        // advance phases
        phaseA += speed_increment;
        phaseB += speed_increment;
        phaseC += speed_increment;

        // Wrap around in both directions
        if (phaseA >= SINE_TABLE_SIZE) phaseA -= SINE_TABLE_SIZE;
        else if (phaseA < 0.0f)        phaseA += SINE_TABLE_SIZE;

        if (phaseB >= SINE_TABLE_SIZE) phaseB -= SINE_TABLE_SIZE;
        else if (phaseB < 0.0f)        phaseB += SINE_TABLE_SIZE;

        if (phaseC >= SINE_TABLE_SIZE) phaseC -= SINE_TABLE_SIZE;
        else if (phaseC < 0.0f)        phaseC += SINE_TABLE_SIZE;

        uint16_t dutyA = (uint16_t)(
            (sine_table[(uint16_t)phaseA] * voltage_amplitude) /
            TIM1_FULL_DUTY
        );
        uint16_t dutyB = (uint16_t)(
            (sine_table[(uint16_t)phaseB] * voltage_amplitude) /
            TIM1_FULL_DUTY
        );
        uint16_t dutyC = (uint16_t)(
            (sine_table[(uint16_t)phaseC] * voltage_amplitude) /
            TIM1_FULL_DUTY
        );

        __HAL_TIM_SET_COMPARE(&htim1, TIM_CHANNEL_1, dutyA);
        __HAL_TIM_SET_COMPARE(&htim1, TIM_CHANNEL_2, dutyB);
        __HAL_TIM_SET_COMPARE(&htim1, TIM_CHANNEL_3, dutyC);

        float ia, ib, ic;
        CurrentSense_GetPhaseCurrents(&ia, &ib, &ic);
        dbg_ia = ia;
        dbg_ib = ib;
        dbg_ic = ic;

    }

    if (htim == &htim7) {
        TLE_Encoder_CalcSpeed(&encoder);
        SpeedLoop_Update();
        if (++pos_loop_divider >= 2) {
            pos_loop_divider = 0;
            PositionLoop_Update(POS_LOOP_DT);
        }
    }
}
// Retarget printf to UART1
int __io_putchar(int ch)
{
    HAL_UART_Transmit(&huart1, (uint8_t*)&ch, 1, HAL_MAX_DELAY);
    return 1;
}

/* USER CODE END 0 */

int main(void)
{

  /* MCU Configuration--------------------------------------------------------*/

  /* Reset of all peripherals, Initializes the Flash interface and the Systick. */
  HAL_Init();

  /* Configure the system clock */
  SystemClock_Config();

  /* Initialize all configured peripherals */
  MX_GPIO_Init();
  MX_DMA_Init();
  MX_FDCAN2_Init();
  MX_ADC1_Init();
  MX_ADC2_Init();
  MX_ADC3_Init();
  MX_ADC5_Init();
  MX_SPI1_Init();
  MX_SPI2_Init();
  MX_SPI3_Init();
  MX_TIM1_Init();
  MX_I2C3_Init();
  MX_USART1_UART_Init();
  MX_I2C4_Init();
  MX_ADC4_Init();
  MX_TIM6_Init();
  MX_IWDG_Init();
  MX_TIM7_Init();
  /* USER CODE BEGIN 2 */
  Generate_Sine_Table();
  DRV8323_Init();
  TLE_Encoder_Init(&encoder, &hspi2, SPI2_NSS_GPIO_Port, SPI2_NSS_Pin);

  HAL_TIM_OC_Start(&htim1, TIM_CHANNEL_5);

  HAL_ADC_Start_DMA(&hadc1, (uint32_t *)&adc_phase_raw[0], 1);  // phase A
  HAL_ADC_Start_DMA(&hadc2, (uint32_t *)&adc_phase_raw[1], 1);  // phase B
  HAL_ADC_Start_DMA(&hadc3, (uint32_t *)&adc_phase_raw[2], 1);  // phase C

  // Start PWM generation
  HAL_TIM_PWM_Start(&htim1, TIM_CHANNEL_1);
  HAL_TIM_PWM_Start(&htim1, TIM_CHANNEL_2);
  HAL_TIM_PWM_Start(&htim1, TIM_CHANNEL_3);
  CurrentSense_CalibrateMidpoints();

  // Start timer interrupt for PWM update
  HAL_TIM_Base_Start_IT(&htim6);
  HAL_TIM_Base_Start_IT(&htim7);

  /* USER CODE END 2 */

  /* Infinite loop */
  /* USER CODE BEGIN WHILE */

  while (1)
  {
	  HAL_IWDG_Refresh(&hiwdg); //odświeżenie niezależnego watchdog'a

	 	  // handle DRV faults first
	 	  DRV8323_ServiceFault();
		  Update_VoltageAmplitude();

	            //CurrentSense_GetPhaseCurrents(&ia, &ib, &ic);

		  if (display_active) {
		      // Motor multi-turn angle
		      float motor_angle_deg = TLE_Encoder_GetAngleMultiDeg(&encoder);
		      // Output shaft angle (multi-turn)
		      float pos_out_deg = motor_angle_deg / GEAR_RATIO;
		      float pos_err_deg = target_pos_out_deg - pos_out_deg;

		      // Use same "target reached" condition as in PositionLoop:
		      // small angle error && almost stopped
		      if (fabsf(pos_err_deg) < POS_DEADBAND_DEG &&
		          fabsf(rpm_filtered) < 1.0f)  // same threshold as in PositionLoop
		      {
		    	  // Add display offset and wrap to 0–360
		    	  float out_disp = pos_out_deg + ANGLE_DISPLAY_OFFSET_DEG;
		    	  float tgt_disp = target_pos_out_deg + ANGLE_DISPLAY_OFFSET_DEG;

		    	  float out_wrapped = fmodf(out_disp, 360.0f);
		    	  if (out_wrapped < 0.0f) out_wrapped += 360.0f;

		    	  float target_wrapped = fmodf(tgt_disp, 360.0f);
		    	  if (target_wrapped < 0.0f) target_wrapped += 360.0f;

		    	  printf(
		    	      "Reached: Out: %.2f deg, Target: %.2f deg, Err: %.2f deg\r\n",
		    	      out_wrapped,
		    	      target_wrapped,
		    	      pos_err_deg
		    	  );

		          // Disable further prints until next command
		          display_active = false;
		      }
		  }

		    uint8_t value;
		    if (HAL_UART_Receive(&huart1, &value, 1, 0) == HAL_OK) {
		        line_append(value);
		    }

    /* USER CODE END WHILE */

  }
}

void SystemClock_Config(void)
{
  RCC_OscInitTypeDef RCC_OscInitStruct = {0};
  RCC_ClkInitTypeDef RCC_ClkInitStruct = {0};

  /** Configure the main internal regulator output voltage
  */
  HAL_PWREx_ControlVoltageScaling(PWR_REGULATOR_VOLTAGE_SCALE1);

  /** Initializes the RCC Oscillators according to the specified parameters
  * in the RCC_OscInitTypeDef structure.
  */
  RCC_OscInitStruct.OscillatorType = RCC_OSCILLATORTYPE_LSI|RCC_OSCILLATORTYPE_HSE;
  RCC_OscInitStruct.HSEState = RCC_HSE_ON;
  RCC_OscInitStruct.LSIState = RCC_LSI_ON;
  RCC_OscInitStruct.PLL.PLLState = RCC_PLL_ON;
  RCC_OscInitStruct.PLL.PLLSource = RCC_PLLSOURCE_HSE;
  RCC_OscInitStruct.PLL.PLLM = RCC_PLLM_DIV3;
  RCC_OscInitStruct.PLL.PLLN = 32;
  RCC_OscInitStruct.PLL.PLLP = RCC_PLLP_DIV2;
  RCC_OscInitStruct.PLL.PLLQ = RCC_PLLQ_DIV2;
  RCC_OscInitStruct.PLL.PLLR = RCC_PLLR_DIV2;
  if (HAL_RCC_OscConfig(&RCC_OscInitStruct) != HAL_OK)
  {
    Error_Handler();
  }

  /** Initializes the CPU, AHB and APB buses clocks
  */
  RCC_ClkInitStruct.ClockType = RCC_CLOCKTYPE_HCLK|RCC_CLOCKTYPE_SYSCLK
                              |RCC_CLOCKTYPE_PCLK1|RCC_CLOCKTYPE_PCLK2;
  RCC_ClkInitStruct.SYSCLKSource = RCC_SYSCLKSOURCE_PLLCLK;
  RCC_ClkInitStruct.AHBCLKDivider = RCC_SYSCLK_DIV1;
  RCC_ClkInitStruct.APB1CLKDivider = RCC_HCLK_DIV1;
  RCC_ClkInitStruct.APB2CLKDivider = RCC_HCLK_DIV1;

  if (HAL_RCC_ClockConfig(&RCC_ClkInitStruct, FLASH_LATENCY_4) != HAL_OK)
  {
    Error_Handler();
  }
}

static void MX_ADC1_Init(void)
{

  ADC_MultiModeTypeDef multimode = {0};
  ADC_ChannelConfTypeDef sConfig = {0};

  /** Common config
  */
  hadc1.Instance = ADC1;
  hadc1.Init.ClockPrescaler = ADC_CLOCK_ASYNC_DIV10;
  hadc1.Init.Resolution = ADC_RESOLUTION_12B;
  hadc1.Init.DataAlign = ADC_DATAALIGN_RIGHT;
  hadc1.Init.GainCompensation = 0;
  hadc1.Init.ScanConvMode = ADC_SCAN_DISABLE;
  hadc1.Init.EOCSelection = ADC_EOC_SINGLE_CONV;
  hadc1.Init.LowPowerAutoWait = DISABLE;
  hadc1.Init.ContinuousConvMode = DISABLE;
  hadc1.Init.NbrOfConversion = 1;
  hadc1.Init.DiscontinuousConvMode = DISABLE;
  hadc1.Init.ExternalTrigConv = ADC_EXTERNALTRIG_T1_TRGO2;
  hadc1.Init.ExternalTrigConvEdge = ADC_EXTERNALTRIGCONVEDGE_RISING;
  hadc1.Init.DMAContinuousRequests = ENABLE;
  hadc1.Init.Overrun = ADC_OVR_DATA_PRESERVED;
  hadc1.Init.OversamplingMode = DISABLE;
  if (HAL_ADC_Init(&hadc1) != HAL_OK)
  {
    Error_Handler();
  }

  /** Configure the ADC multi-mode
  */
  multimode.Mode = ADC_MODE_INDEPENDENT;
  if (HAL_ADCEx_MultiModeConfigChannel(&hadc1, &multimode) != HAL_OK)
  {
    Error_Handler();
  }

  /** Configure Regular Channel
  */
  sConfig.Channel = ADC_CHANNEL_1;
  sConfig.Rank = ADC_REGULAR_RANK_1;
  sConfig.SamplingTime = ADC_SAMPLETIME_6CYCLES_5;
  sConfig.SingleDiff = ADC_SINGLE_ENDED;
  sConfig.OffsetNumber = ADC_OFFSET_NONE;
  sConfig.Offset = 0;
  if (HAL_ADC_ConfigChannel(&hadc1, &sConfig) != HAL_OK)
  {
    Error_Handler();
  }

}

static void MX_ADC2_Init(void)
{

  ADC_ChannelConfTypeDef sConfig = {0};

  /** Common config
  */
  hadc2.Instance = ADC2;
  hadc2.Init.ClockPrescaler = ADC_CLOCK_ASYNC_DIV10;
  hadc2.Init.Resolution = ADC_RESOLUTION_12B;
  hadc2.Init.DataAlign = ADC_DATAALIGN_RIGHT;
  hadc2.Init.GainCompensation = 0;
  hadc2.Init.ScanConvMode = ADC_SCAN_DISABLE;
  hadc2.Init.EOCSelection = ADC_EOC_SINGLE_CONV;
  hadc2.Init.LowPowerAutoWait = DISABLE;
  hadc2.Init.ContinuousConvMode = DISABLE;
  hadc2.Init.NbrOfConversion = 1;
  hadc2.Init.DiscontinuousConvMode = DISABLE;
  hadc2.Init.ExternalTrigConv = ADC_EXTERNALTRIG_T1_TRGO2;
  hadc2.Init.ExternalTrigConvEdge = ADC_EXTERNALTRIGCONVEDGE_RISING;
  hadc2.Init.DMAContinuousRequests = ENABLE;
  hadc2.Init.Overrun = ADC_OVR_DATA_PRESERVED;
  hadc2.Init.OversamplingMode = DISABLE;
  if (HAL_ADC_Init(&hadc2) != HAL_OK)
  {
    Error_Handler();
  }

  /** Configure Regular Channel
  */
  sConfig.Channel = ADC_CHANNEL_2;
  sConfig.Rank = ADC_REGULAR_RANK_1;
  sConfig.SamplingTime = ADC_SAMPLETIME_6CYCLES_5;
  sConfig.SingleDiff = ADC_SINGLE_ENDED;
  sConfig.OffsetNumber = ADC_OFFSET_NONE;
  sConfig.Offset = 0;
  if (HAL_ADC_ConfigChannel(&hadc2, &sConfig) != HAL_OK)
  {
    Error_Handler();
  }

}

static void MX_ADC3_Init(void)
{

  ADC_MultiModeTypeDef multimode = {0};
  ADC_ChannelConfTypeDef sConfig = {0};

  /** Common config
  */
  hadc3.Instance = ADC3;
  hadc3.Init.ClockPrescaler = ADC_CLOCK_ASYNC_DIV10;
  hadc3.Init.Resolution = ADC_RESOLUTION_12B;
  hadc3.Init.DataAlign = ADC_DATAALIGN_RIGHT;
  hadc3.Init.GainCompensation = 0;
  hadc3.Init.ScanConvMode = ADC_SCAN_DISABLE;
  hadc3.Init.EOCSelection = ADC_EOC_SINGLE_CONV;
  hadc3.Init.LowPowerAutoWait = DISABLE;
  hadc3.Init.ContinuousConvMode = DISABLE;
  hadc3.Init.NbrOfConversion = 1;
  hadc3.Init.DiscontinuousConvMode = DISABLE;
  hadc3.Init.ExternalTrigConv = ADC_EXTERNALTRIG_T1_TRGO2;
  hadc3.Init.ExternalTrigConvEdge = ADC_EXTERNALTRIGCONVEDGE_RISING;
  hadc3.Init.DMAContinuousRequests = ENABLE;
  hadc3.Init.Overrun = ADC_OVR_DATA_PRESERVED;
  hadc3.Init.OversamplingMode = DISABLE;
  if (HAL_ADC_Init(&hadc3) != HAL_OK)
  {
    Error_Handler();
  }

  /** Configure the ADC multi-mode
  */
  multimode.Mode = ADC_MODE_INDEPENDENT;
  if (HAL_ADCEx_MultiModeConfigChannel(&hadc3, &multimode) != HAL_OK)
  {
    Error_Handler();
  }

  /** Configure Regular Channel
  */
  sConfig.Channel = ADC_CHANNEL_1;
  sConfig.Rank = ADC_REGULAR_RANK_1;
  sConfig.SamplingTime = ADC_SAMPLETIME_6CYCLES_5;
  sConfig.SingleDiff = ADC_SINGLE_ENDED;
  sConfig.OffsetNumber = ADC_OFFSET_NONE;
  sConfig.Offset = 0;
  if (HAL_ADC_ConfigChannel(&hadc3, &sConfig) != HAL_OK)
  {
    Error_Handler();
  }

}

static void MX_ADC4_Init(void)
{

  ADC_ChannelConfTypeDef sConfig = {0};

  /** Common config
  */
  hadc4.Instance = ADC4;
  hadc4.Init.ClockPrescaler = ADC_CLOCK_ASYNC_DIV10;
  hadc4.Init.Resolution = ADC_RESOLUTION_12B;
  hadc4.Init.DataAlign = ADC_DATAALIGN_RIGHT;
  hadc4.Init.GainCompensation = 0;
  hadc4.Init.ScanConvMode = ADC_SCAN_DISABLE;
  hadc4.Init.EOCSelection = ADC_EOC_SINGLE_CONV;
  hadc4.Init.LowPowerAutoWait = DISABLE;
  hadc4.Init.ContinuousConvMode = DISABLE;
  hadc4.Init.NbrOfConversion = 1;
  hadc4.Init.DiscontinuousConvMode = DISABLE;
  hadc4.Init.ExternalTrigConv = ADC_SOFTWARE_START;
  hadc4.Init.ExternalTrigConvEdge = ADC_EXTERNALTRIGCONVEDGE_NONE;
  hadc4.Init.DMAContinuousRequests = DISABLE;
  hadc4.Init.Overrun = ADC_OVR_DATA_PRESERVED;
  hadc4.Init.OversamplingMode = DISABLE;
  if (HAL_ADC_Init(&hadc4) != HAL_OK)
  {
    Error_Handler();
  }

  /** Configure Regular Channel
  */
  sConfig.Channel = ADC_CHANNEL_3;
  sConfig.Rank = ADC_REGULAR_RANK_1;
  sConfig.SamplingTime = ADC_SAMPLETIME_2CYCLES_5;
  sConfig.SingleDiff = ADC_SINGLE_ENDED;
  sConfig.OffsetNumber = ADC_OFFSET_NONE;
  sConfig.Offset = 0;
  if (HAL_ADC_ConfigChannel(&hadc4, &sConfig) != HAL_OK)
  {
    Error_Handler();
  }

}

static void MX_ADC5_Init(void)
{

  ADC_ChannelConfTypeDef sConfig = {0};

  /** Common config
  */
  hadc5.Instance = ADC5;
  hadc5.Init.ClockPrescaler = ADC_CLOCK_ASYNC_DIV10;
  hadc5.Init.Resolution = ADC_RESOLUTION_12B;
  hadc5.Init.DataAlign = ADC_DATAALIGN_RIGHT;
  hadc5.Init.GainCompensation = 0;
  hadc5.Init.ScanConvMode = ADC_SCAN_DISABLE;
  hadc5.Init.EOCSelection = ADC_EOC_SINGLE_CONV;
  hadc5.Init.LowPowerAutoWait = DISABLE;
  hadc5.Init.ContinuousConvMode = ENABLE;
  hadc5.Init.NbrOfConversion = 1;
  hadc5.Init.DiscontinuousConvMode = DISABLE;
  hadc5.Init.ExternalTrigConv = ADC_SOFTWARE_START;
  hadc5.Init.ExternalTrigConvEdge = ADC_EXTERNALTRIGCONVEDGE_NONE;
  hadc5.Init.DMAContinuousRequests = DISABLE;
  hadc5.Init.Overrun = ADC_OVR_DATA_PRESERVED;
  hadc5.Init.OversamplingMode = DISABLE;
  if (HAL_ADC_Init(&hadc5) != HAL_OK)
  {
    Error_Handler();
  }

  /** Configure Regular Channel
  */
  sConfig.Channel = ADC_CHANNEL_1;
  sConfig.Rank = ADC_REGULAR_RANK_1;
  sConfig.SamplingTime = ADC_SAMPLETIME_2CYCLES_5;
  sConfig.SingleDiff = ADC_SINGLE_ENDED;
  sConfig.OffsetNumber = ADC_OFFSET_NONE;
  sConfig.Offset = 0;
  if (HAL_ADC_ConfigChannel(&hadc5, &sConfig) != HAL_OK)
  {
    Error_Handler();
  }

}

static void MX_FDCAN2_Init(void)
{

  hfdcan2.Instance = FDCAN2;
  hfdcan2.Init.ClockDivider = FDCAN_CLOCK_DIV1;
  hfdcan2.Init.FrameFormat = FDCAN_FRAME_CLASSIC;
  hfdcan2.Init.Mode = FDCAN_MODE_NORMAL;
  hfdcan2.Init.AutoRetransmission = ENABLE;
  hfdcan2.Init.TransmitPause = DISABLE;
  hfdcan2.Init.ProtocolException = DISABLE;
  hfdcan2.Init.NominalPrescaler = 16;
  hfdcan2.Init.NominalSyncJumpWidth = 1;
  hfdcan2.Init.NominalTimeSeg1 = 1;
  hfdcan2.Init.NominalTimeSeg2 = 1;
  hfdcan2.Init.DataPrescaler = 1;
  hfdcan2.Init.DataSyncJumpWidth = 1;
  hfdcan2.Init.DataTimeSeg1 = 1;
  hfdcan2.Init.DataTimeSeg2 = 1;
  hfdcan2.Init.StdFiltersNbr = 0;
  hfdcan2.Init.ExtFiltersNbr = 0;
  hfdcan2.Init.TxFifoQueueMode = FDCAN_TX_FIFO_OPERATION;
  if (HAL_FDCAN_Init(&hfdcan2) != HAL_OK)
  {
    Error_Handler();
  }

}

static void MX_I2C3_Init(void)
{

  hi2c3.Instance = I2C3;
  hi2c3.Init.Timing = 0x20E2A7F4;
  hi2c3.Init.OwnAddress1 = 0;
  hi2c3.Init.AddressingMode = I2C_ADDRESSINGMODE_7BIT;
  hi2c3.Init.DualAddressMode = I2C_DUALADDRESS_DISABLE;
  hi2c3.Init.OwnAddress2 = 0;
  hi2c3.Init.OwnAddress2Masks = I2C_OA2_NOMASK;
  hi2c3.Init.GeneralCallMode = I2C_GENERALCALL_DISABLE;
  hi2c3.Init.NoStretchMode = I2C_NOSTRETCH_DISABLE;
  if (HAL_I2C_Init(&hi2c3) != HAL_OK)
  {
    Error_Handler();
  }

  /** Configure Analogue filter
  */
  if (HAL_I2CEx_ConfigAnalogFilter(&hi2c3, I2C_ANALOGFILTER_ENABLE) != HAL_OK)
  {
    Error_Handler();
  }

  /** Configure Digital filter
  */
  if (HAL_I2CEx_ConfigDigitalFilter(&hi2c3, 0) != HAL_OK)
  {
    Error_Handler();
  }

}

static void MX_I2C4_Init(void)
{

  hi2c4.Instance = I2C4;
  hi2c4.Init.Timing = 0x20E2A7F4;
  hi2c4.Init.OwnAddress1 = 0;
  hi2c4.Init.AddressingMode = I2C_ADDRESSINGMODE_7BIT;
  hi2c4.Init.DualAddressMode = I2C_DUALADDRESS_DISABLE;
  hi2c4.Init.OwnAddress2 = 0;
  hi2c4.Init.OwnAddress2Masks = I2C_OA2_NOMASK;
  hi2c4.Init.GeneralCallMode = I2C_GENERALCALL_DISABLE;
  hi2c4.Init.NoStretchMode = I2C_NOSTRETCH_DISABLE;
  if (HAL_I2C_Init(&hi2c4) != HAL_OK)
  {
    Error_Handler();
  }

  /** Configure Analogue filter
  */
  if (HAL_I2CEx_ConfigAnalogFilter(&hi2c4, I2C_ANALOGFILTER_ENABLE) != HAL_OK)
  {
    Error_Handler();
  }

  /** Configure Digital filter
  */
  if (HAL_I2CEx_ConfigDigitalFilter(&hi2c4, 0) != HAL_OK)
  {
    Error_Handler();
  }

}

static void MX_IWDG_Init(void)
{

  hiwdg.Instance = IWDG;
  hiwdg.Init.Prescaler = IWDG_PRESCALER_32;
  hiwdg.Init.Window = 4095;
  hiwdg.Init.Reload = 4095;
  if (HAL_IWDG_Init(&hiwdg) != HAL_OK)
  {
    Error_Handler();
  }

}

static void MX_SPI1_Init(void)
{

  /* SPI1 parameter configuration*/
  hspi1.Instance = SPI1;
  hspi1.Init.Mode = SPI_MODE_MASTER;
  hspi1.Init.Direction = SPI_DIRECTION_2LINES;
  hspi1.Init.DataSize = SPI_DATASIZE_16BIT;
  hspi1.Init.CLKPolarity = SPI_POLARITY_LOW;
  hspi1.Init.CLKPhase = SPI_PHASE_2EDGE;
  hspi1.Init.NSS = SPI_NSS_SOFT;
  hspi1.Init.BaudRatePrescaler = SPI_BAUDRATEPRESCALER_128;
  hspi1.Init.FirstBit = SPI_FIRSTBIT_MSB;
  hspi1.Init.TIMode = SPI_TIMODE_DISABLE;
  hspi1.Init.CRCCalculation = SPI_CRCCALCULATION_DISABLE;
  hspi1.Init.CRCPolynomial = 7;
  hspi1.Init.CRCLength = SPI_CRC_LENGTH_DATASIZE;
  hspi1.Init.NSSPMode = SPI_NSS_PULSE_DISABLE;
  if (HAL_SPI_Init(&hspi1) != HAL_OK)
  {
    Error_Handler();
  }

}

static void MX_SPI2_Init(void)
{

  /* SPI2 parameter configuration*/
  hspi2.Instance = SPI2;
  hspi2.Init.Mode = SPI_MODE_MASTER;
  hspi2.Init.Direction = SPI_DIRECTION_1LINE;
  hspi2.Init.DataSize = SPI_DATASIZE_8BIT;
  hspi2.Init.CLKPolarity = SPI_POLARITY_LOW;
  hspi2.Init.CLKPhase = SPI_PHASE_2EDGE;
  hspi2.Init.NSS = SPI_NSS_SOFT;
  hspi2.Init.BaudRatePrescaler = SPI_BAUDRATEPRESCALER_128;
  hspi2.Init.FirstBit = SPI_FIRSTBIT_MSB;
  hspi2.Init.TIMode = SPI_TIMODE_DISABLE;
  hspi2.Init.CRCCalculation = SPI_CRCCALCULATION_DISABLE;
  hspi2.Init.CRCPolynomial = 7;
  hspi2.Init.CRCLength = SPI_CRC_LENGTH_DATASIZE;
  hspi2.Init.NSSPMode = SPI_NSS_PULSE_DISABLE;
  if (HAL_SPI_Init(&hspi2) != HAL_OK)
  {
    Error_Handler();
  }

}

static void MX_SPI3_Init(void)
{

  /* SPI3 parameter configuration*/
  hspi3.Instance = SPI3;
  hspi3.Init.Mode = SPI_MODE_MASTER;
  hspi3.Init.Direction = SPI_DIRECTION_1LINE;
  hspi3.Init.DataSize = SPI_DATASIZE_4BIT;
  hspi3.Init.CLKPolarity = SPI_POLARITY_LOW;
  hspi3.Init.CLKPhase = SPI_PHASE_1EDGE;
  hspi3.Init.NSS = SPI_NSS_SOFT;
  hspi3.Init.BaudRatePrescaler = SPI_BAUDRATEPRESCALER_2;
  hspi3.Init.FirstBit = SPI_FIRSTBIT_MSB;
  hspi3.Init.TIMode = SPI_TIMODE_DISABLE;
  hspi3.Init.CRCCalculation = SPI_CRCCALCULATION_DISABLE;
  hspi3.Init.CRCPolynomial = 7;
  hspi3.Init.CRCLength = SPI_CRC_LENGTH_DATASIZE;
  hspi3.Init.NSSPMode = SPI_NSS_PULSE_ENABLE;
  if (HAL_SPI_Init(&hspi3) != HAL_OK)
  {
    Error_Handler();
  }

}

static void MX_TIM1_Init(void)
{

  TIM_ClockConfigTypeDef sClockSourceConfig = {0};
  TIM_MasterConfigTypeDef sMasterConfig = {0};
  TIM_OC_InitTypeDef sConfigOC = {0};
  TIM_BreakDeadTimeConfigTypeDef sBreakDeadTimeConfig = {0};

  htim1.Instance = TIM1;
  htim1.Init.Prescaler = 0;
  htim1.Init.CounterMode = TIM_COUNTERMODE_CENTERALIGNED1;
  htim1.Init.Period = 3199;
  htim1.Init.ClockDivision = TIM_CLOCKDIVISION_DIV1;
  htim1.Init.RepetitionCounter = 0;
  htim1.Init.AutoReloadPreload = TIM_AUTORELOAD_PRELOAD_DISABLE;
  if (HAL_TIM_Base_Init(&htim1) != HAL_OK)
  {
    Error_Handler();
  }
  sClockSourceConfig.ClockSource = TIM_CLOCKSOURCE_INTERNAL;
  if (HAL_TIM_ConfigClockSource(&htim1, &sClockSourceConfig) != HAL_OK)
  {
    Error_Handler();
  }
  if (HAL_TIM_PWM_Init(&htim1) != HAL_OK)
  {
    Error_Handler();
  }
  if (HAL_TIM_OC_Init(&htim1) != HAL_OK)
  {
    Error_Handler();
  }
  sMasterConfig.MasterOutputTrigger = TIM_TRGO_RESET;
  sMasterConfig.MasterOutputTrigger2 = TIM_TRGO2_OC5REF;
  sMasterConfig.MasterSlaveMode = TIM_MASTERSLAVEMODE_DISABLE;
  if (HAL_TIMEx_MasterConfigSynchronization(&htim1, &sMasterConfig) != HAL_OK)
  {
    Error_Handler();
  }
  sConfigOC.OCMode = TIM_OCMODE_PWM1;
  sConfigOC.Pulse = 0;
  sConfigOC.OCPolarity = TIM_OCPOLARITY_HIGH;
  sConfigOC.OCNPolarity = TIM_OCNPOLARITY_HIGH;
  sConfigOC.OCFastMode = TIM_OCFAST_DISABLE;
  sConfigOC.OCIdleState = TIM_OCIDLESTATE_RESET;
  sConfigOC.OCNIdleState = TIM_OCNIDLESTATE_RESET;
  if (HAL_TIM_PWM_ConfigChannel(&htim1, &sConfigOC, TIM_CHANNEL_1) != HAL_OK)
  {
    Error_Handler();
  }
  if (HAL_TIM_PWM_ConfigChannel(&htim1, &sConfigOC, TIM_CHANNEL_2) != HAL_OK)
  {
    Error_Handler();
  }
  if (HAL_TIM_PWM_ConfigChannel(&htim1, &sConfigOC, TIM_CHANNEL_3) != HAL_OK)
  {
    Error_Handler();
  }
  if (HAL_TIM_PWM_ConfigChannel(&htim1, &sConfigOC, TIM_CHANNEL_4) != HAL_OK)
  {
    Error_Handler();
  }
  sConfigOC.OCMode = TIM_OCMODE_TOGGLE;
  sConfigOC.Pulse = 1599;
  if (HAL_TIM_OC_ConfigChannel(&htim1, &sConfigOC, TIM_CHANNEL_5) != HAL_OK)
  {
    Error_Handler();
  }
  sBreakDeadTimeConfig.OffStateRunMode = TIM_OSSR_DISABLE;
  sBreakDeadTimeConfig.OffStateIDLEMode = TIM_OSSI_DISABLE;
  sBreakDeadTimeConfig.LockLevel = TIM_LOCKLEVEL_OFF;
  sBreakDeadTimeConfig.DeadTime = 0;
  sBreakDeadTimeConfig.BreakState = TIM_BREAK_DISABLE;
  sBreakDeadTimeConfig.BreakPolarity = TIM_BREAKPOLARITY_HIGH;
  sBreakDeadTimeConfig.BreakFilter = 0;
  sBreakDeadTimeConfig.BreakAFMode = TIM_BREAK_AFMODE_INPUT;
  sBreakDeadTimeConfig.Break2State = TIM_BREAK2_DISABLE;
  sBreakDeadTimeConfig.Break2Polarity = TIM_BREAK2POLARITY_HIGH;
  sBreakDeadTimeConfig.Break2Filter = 0;
  sBreakDeadTimeConfig.Break2AFMode = TIM_BREAK_AFMODE_INPUT;
  sBreakDeadTimeConfig.AutomaticOutput = TIM_AUTOMATICOUTPUT_DISABLE;
  if (HAL_TIMEx_ConfigBreakDeadTime(&htim1, &sBreakDeadTimeConfig) != HAL_OK)
  {
    Error_Handler();
  }
  HAL_TIM_MspPostInit(&htim1);

}

static void MX_TIM6_Init(void)
{

  TIM_MasterConfigTypeDef sMasterConfig = {0};

  htim6.Instance = TIM6;
  htim6.Init.Prescaler = 0;
  htim6.Init.CounterMode = TIM_COUNTERMODE_UP;
  htim6.Init.Period = 25599;
  htim6.Init.AutoReloadPreload = TIM_AUTORELOAD_PRELOAD_DISABLE;
  if (HAL_TIM_Base_Init(&htim6) != HAL_OK)
  {
    Error_Handler();
  }
  sMasterConfig.MasterOutputTrigger = TIM_TRGO_RESET;
  sMasterConfig.MasterSlaveMode = TIM_MASTERSLAVEMODE_DISABLE;
  if (HAL_TIMEx_MasterConfigSynchronization(&htim6, &sMasterConfig) != HAL_OK)
  {
    Error_Handler();
  }

}

static void MX_TIM7_Init(void)
{

  TIM_MasterConfigTypeDef sMasterConfig = {0};

  htim7.Instance = TIM7;
  htim7.Init.Prescaler = 15;
  htim7.Init.CounterMode = TIM_COUNTERMODE_UP;
  htim7.Init.Period = 39999;
  htim7.Init.AutoReloadPreload = TIM_AUTORELOAD_PRELOAD_DISABLE;
  if (HAL_TIM_Base_Init(&htim7) != HAL_OK)
  {
    Error_Handler();
  }
  sMasterConfig.MasterOutputTrigger = TIM_TRGO_RESET;
  sMasterConfig.MasterSlaveMode = TIM_MASTERSLAVEMODE_DISABLE;
  if (HAL_TIMEx_MasterConfigSynchronization(&htim7, &sMasterConfig) != HAL_OK)
  {
    Error_Handler();
  }

}

static void MX_USART1_UART_Init(void)
{

  huart1.Instance = USART1;
  huart1.Init.BaudRate = 115200;
  huart1.Init.WordLength = UART_WORDLENGTH_8B;
  huart1.Init.StopBits = UART_STOPBITS_1;
  huart1.Init.Parity = UART_PARITY_NONE;
  huart1.Init.Mode = UART_MODE_TX_RX;
  huart1.Init.HwFlowCtl = UART_HWCONTROL_NONE;
  huart1.Init.OverSampling = UART_OVERSAMPLING_16;
  huart1.Init.OneBitSampling = UART_ONE_BIT_SAMPLE_DISABLE;
  huart1.Init.ClockPrescaler = UART_PRESCALER_DIV1;
  huart1.AdvancedInit.AdvFeatureInit = UART_ADVFEATURE_NO_INIT;
  if (HAL_UART_Init(&huart1) != HAL_OK)
  {
    Error_Handler();
  }
  if (HAL_UARTEx_SetTxFifoThreshold(&huart1, UART_TXFIFO_THRESHOLD_1_8) != HAL_OK)
  {
    Error_Handler();
  }
  if (HAL_UARTEx_SetRxFifoThreshold(&huart1, UART_RXFIFO_THRESHOLD_1_8) != HAL_OK)
  {
    Error_Handler();
  }
  if (HAL_UARTEx_DisableFifoMode(&huart1) != HAL_OK)
  {
    Error_Handler();
  }

}

static void MX_DMA_Init(void)
{

  /* DMA controller clock enable */
  __HAL_RCC_DMAMUX1_CLK_ENABLE();
  __HAL_RCC_DMA1_CLK_ENABLE();

  /* DMA interrupt init */
  /* DMA1_Channel1_IRQn interrupt configuration */
  HAL_NVIC_SetPriority(DMA1_Channel1_IRQn, 0, 0);
  HAL_NVIC_EnableIRQ(DMA1_Channel1_IRQn);
  /* DMA1_Channel2_IRQn interrupt configuration */
  HAL_NVIC_SetPriority(DMA1_Channel2_IRQn, 0, 0);
  HAL_NVIC_EnableIRQ(DMA1_Channel2_IRQn);
  /* DMA1_Channel3_IRQn interrupt configuration */
  HAL_NVIC_SetPriority(DMA1_Channel3_IRQn, 0, 0);
  HAL_NVIC_EnableIRQ(DMA1_Channel3_IRQn);

}

static void MX_GPIO_Init(void)
{
  GPIO_InitTypeDef GPIO_InitStruct = {0};

  /* GPIO Ports Clock Enable */
  __HAL_RCC_GPIOC_CLK_ENABLE();
  __HAL_RCC_GPIOF_CLK_ENABLE();
  __HAL_RCC_GPIOA_CLK_ENABLE();
  __HAL_RCC_GPIOB_CLK_ENABLE();
  __HAL_RCC_GPIOD_CLK_ENABLE();

  /*Configure GPIO pin Output Level */
  HAL_GPIO_WritePin(GPIOC, EEPROM_WP_Pin|M_HIZ_Pin, GPIO_PIN_RESET);

  /*Configure GPIO pin Output Level */
  HAL_GPIO_WritePin(GPIOA, M_EN_Pin|CAL_Pin, GPIO_PIN_RESET);

  /*Configure GPIO pin Output Level */
  HAL_GPIO_WritePin(GPIOA, DRV_CS_Pin|FAULT_Pin|LINK_Pin, GPIO_PIN_SET);

  /*Configure GPIO pin Output Level */
  HAL_GPIO_WritePin(SPI2_NSS_GPIO_Port, SPI2_NSS_Pin, GPIO_PIN_SET);

  /*Configure GPIO pin Output Level */
  HAL_GPIO_WritePin(SPI3_CS_GPIO_Port, SPI3_CS_Pin, GPIO_PIN_SET);

  /*Configure GPIO pin Output Level */
  HAL_GPIO_WritePin(FAN_GPIO_Port, FAN_Pin, GPIO_PIN_RESET);

  /*Configure GPIO pins : EEPROM_WP_Pin M_HIZ_Pin SPI3_CS_Pin */
  GPIO_InitStruct.Pin = EEPROM_WP_Pin|M_HIZ_Pin|SPI3_CS_Pin;
  GPIO_InitStruct.Mode = GPIO_MODE_OUTPUT_PP;
  GPIO_InitStruct.Pull = GPIO_NOPULL;
  GPIO_InitStruct.Speed = GPIO_SPEED_FREQ_LOW;
  HAL_GPIO_Init(GPIOC, &GPIO_InitStruct);

  /*Configure GPIO pin : M_nFault_Pin */
  GPIO_InitStruct.Pin = M_nFault_Pin;
  GPIO_InitStruct.Mode = GPIO_MODE_IT_FALLING;
  GPIO_InitStruct.Pull = GPIO_NOPULL;
  HAL_GPIO_Init(M_nFault_GPIO_Port, &GPIO_InitStruct);

  /*Configure GPIO pins : M_EN_Pin CAL_Pin DRV_CS_Pin FAULT_Pin
                           LINK_Pin */
  GPIO_InitStruct.Pin = M_EN_Pin|CAL_Pin|DRV_CS_Pin|FAULT_Pin
                          |LINK_Pin;
  GPIO_InitStruct.Mode = GPIO_MODE_OUTPUT_PP;
  GPIO_InitStruct.Pull = GPIO_NOPULL;
  GPIO_InitStruct.Speed = GPIO_SPEED_FREQ_LOW;
  HAL_GPIO_Init(GPIOA, &GPIO_InitStruct);

  /*Configure GPIO pin : SPI2_NSS_Pin */
  GPIO_InitStruct.Pin = SPI2_NSS_Pin;
  GPIO_InitStruct.Mode = GPIO_MODE_OUTPUT_PP;
  GPIO_InitStruct.Pull = GPIO_NOPULL;
  GPIO_InitStruct.Speed = GPIO_SPEED_FREQ_LOW;
  HAL_GPIO_Init(SPI2_NSS_GPIO_Port, &GPIO_InitStruct);

  /*Configure GPIO pin : Endstop_Pin */
  GPIO_InitStruct.Pin = Endstop_Pin;
  GPIO_InitStruct.Mode = GPIO_MODE_IT_RISING;
  GPIO_InitStruct.Pull = GPIO_NOPULL;
  HAL_GPIO_Init(Endstop_GPIO_Port, &GPIO_InitStruct);

  /*Configure GPIO pin : FAN_Pin */
  GPIO_InitStruct.Pin = FAN_Pin;
  GPIO_InitStruct.Mode = GPIO_MODE_OUTPUT_PP;
  GPIO_InitStruct.Pull = GPIO_NOPULL;
  GPIO_InitStruct.Speed = GPIO_SPEED_FREQ_LOW;
  HAL_GPIO_Init(FAN_GPIO_Port, &GPIO_InitStruct);

  /*Configure GPIO pins : BTN_A_Pin BTN_B_Pin */
  GPIO_InitStruct.Pin = BTN_A_Pin|BTN_B_Pin;
  GPIO_InitStruct.Mode = GPIO_MODE_IT_FALLING;
  GPIO_InitStruct.Pull = GPIO_PULLUP;
  HAL_GPIO_Init(GPIOB, &GPIO_InitStruct);

  /* EXTI interrupt init*/
  HAL_NVIC_SetPriority(EXTI9_5_IRQn, 2, 0);
  HAL_NVIC_EnableIRQ(EXTI9_5_IRQn);

  HAL_NVIC_SetPriority(EXTI15_10_IRQn, 3, 0);
  HAL_NVIC_EnableIRQ(EXTI15_10_IRQn);

}

void Error_Handler(void)
{
  __disable_irq();
  while (1)
  {
  }
}
